# RP2350 register map
Vendor: Raspberry Pi; Series: RP; File version: 0.1
CPU: CM33 r1p0, little endian, MPU, FPU, DSP, VTOR, 4 interrupt priority bits, 52 interrupts, 8 SAU regions
Registers are 32-bit, read-write, reset 0x0 unless marked. A register's access mark holds for its fields unless they carry their own. Offsets are from the block's base; [hi:lo] are bit positions; {n}, {i} and the like mark numbered series; <NAME> marks a mode.

## SYSCFG — Register block for various chip control signals
Base 0x40008000
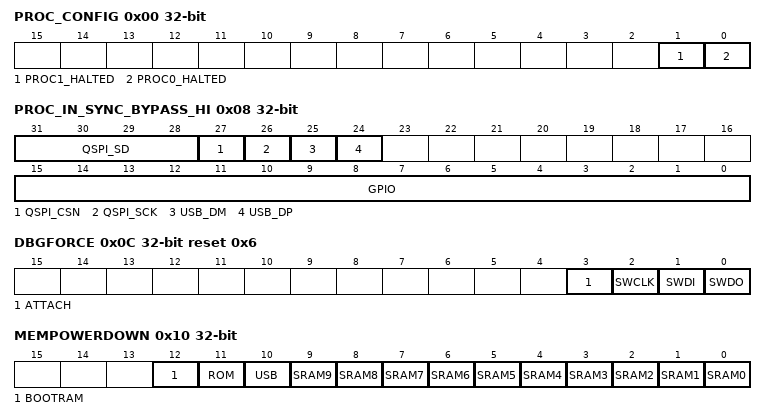
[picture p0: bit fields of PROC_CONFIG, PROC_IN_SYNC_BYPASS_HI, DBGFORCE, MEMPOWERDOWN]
0x00 PROC_CONFIG — Configuration for processors
  [1] PROC1_HALTED ro — Indication that proc1 has halted
  [0] PROC0_HALTED ro — Indication that proc0 has halted
0x04 PROC_IN_SYNC_BYPASS — For each bit, if 1, bypass the input synchronizer between that GPIO and the GPIO input register in the SIO. The input synchronizers should generally be unbypassed, to avoid injecting metastabilities into processors. If you're feeling brave, you can bypass to save two cycles of input latency. This register applies to GPIO 0...31.
  [31:0] GPIO — Pre-defined description
0x08 PROC_IN_SYNC_BYPASS_HI — For each bit, if 1, bypass the input synchronizer between that GPIO and the GPIO input register in the SIO. The input synchronizers should generally be unbypassed, to avoid injecting metastabilities into processors. If you're feeling brave, you can bypass to save two cycles of input latency. This register applies to GPIO 32...47. USB GPIO 56..57 QSPI GPIO 58..63
  [31:28] QSPI_SD — Pre-defined description
  [27] QSPI_CSN — Pre-defined description
  [26] QSPI_SCK — Pre-defined description
  [25] USB_DM — Pre-defined description
  [24] USB_DP — Pre-defined description
  [15:0] GPIO — Pre-defined description
0x0C DBGFORCE reset 0x6 — Directly control the chip SWD debug port
  [3] ATTACH — Attach chip debug port to syscfg controls, and disconnect it from external SWD pads.
  [2] SWCLK — Directly drive SWCLK, if ATTACH is set
  [1] SWDI — Directly drive SWDIO input, if ATTACH is set
  [0] SWDO ro — Observe the value of SWDIO output.
0x10 MEMPOWERDOWN — Control PD pins to memories. Set high to put memories to a low power state. In this state the memories will retain contents but not be accessible Use with caution
  [12] BOOTRAM — Pre-defined description
  [11] ROM — Pre-defined description
  [10] USB — Pre-defined description
  [n] SRAM{n} (n=0..9) — Pre-defined description
0x14 AUXCTRL — Auxiliary system control register
  [7:0] AUXCTRL — * Bits 7:2: Reserved * Bit 1: When clear, the LPOSC output is XORed into the TRNG ROSC output as an additional, uncorrelated entropy source. When set, this behaviour is disabled. * Bit 0: Force POWMAN clock to switch to LPOSC, by asserting its WDRESET input. This must be set before initiating a watchdog reset of the RSM from a stage that includes CLOCKS, if POWMAN is running from clk_ref at the point that the watchdog reset takes place. Otherwise, the short pulse generated on clk_ref by the reset of the CLOCKS block may affect POWMAN register state.

## XOSC — Controls the crystal oscillator
Base 0x40048000
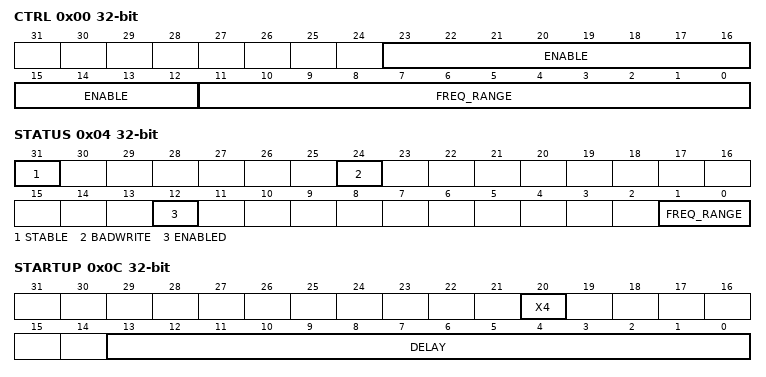
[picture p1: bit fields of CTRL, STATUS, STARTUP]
0x00 CTRL — Crystal Oscillator Control
  [23:12] ENABLE — On power-up this field is initialised to DISABLE and the chip runs from the ROSC. If the chip has subsequently been programmed to run from the XOSC then setting this field to DISABLE may lock-up the chip. If this is a concern then run the clk_ref from the ROSC and enable the clk_sys RESUS feature. The 12-bit code is intended to give some protection against accidental writes. An invalid setting will retain the previous value. The actual value being used can be read from STATUS_ENABLED
    0xD1E=DISABLE; 0xFAB=ENABLE
  [11:0] FREQ_RANGE — The 12-bit code is intended to give some protection against accidental writes. An invalid setting will retain the previous value. The actual value being used can be read from STATUS_FREQ_RANGE
    0xAA0=1_15MHZ; 0xAA1=10_30MHZ; 0xAA2=25_60MHZ; 0xAA3=40_100MHZ
0x04 STATUS — Crystal Oscillator Status
  [31] STABLE ro — Oscillator is running and stable
  [24] BADWRITE write-1-clears — An invalid value has been written to CTRL_ENABLE or CTRL_FREQ_RANGE or DORMANT
  [12] ENABLED ro — Oscillator is enabled but not necessarily running and stable, resets to 0
  [1:0] FREQ_RANGE ro — The current frequency range setting
    0=1_15MHZ; 1=10_30MHZ; 2=25_60MHZ; 3=40_100MHZ
0x08 DORMANT reset not defined — Crystal Oscillator pause control
  [31:0] DORMANT — This is used to save power by pausing the XOSC On power-up this field is initialised to WAKE An invalid write will also select WAKE Warning: stop the PLLs before selecting dormant mode Warning: setup the irq before selecting dormant mode
    0x636F6D61=dormant; 0x77616B65=WAKE
0x0C STARTUP — Controls the startup delay
  [20] X4 — Multiplies the startup_delay by 4, just in case. The reset value is controlled by a mask-programmable tiecell and is provided in case we are booting from XOSC and the default startup delay is insufficient. The reset value is 0x0.
  [13:0] DELAY — in multiples of 256*xtal_period. The reset value of 0xc4 corresponds to approx 50 000 cycles.
0x10 COUNT — A down counter running at the xosc frequency which counts to zero and stops. Can be used for short software pauses when setting up time sensitive hardware. To start the counter, write a non-zero value. Reads will return 1 while the count is running and 0 when it has finished. Minimum count value is 4. Count values <4 will be treated as count value =4. Note that synchronisation to the register clock domain costs 2 register clock cycles and the counter cannot compensate for that.
  [15:0] COUNT — Pre-defined description
